# psoc6a2m register map
Vendor: Cypress Semiconductor; Series: psoc6a2m; File version: 1.0
CPU: CM4 r0p1, little endian, MPU, FPU, VTOR, 3 interrupt priority bits
Registers are 32-bit, read-write, reset 0x0 unless marked. A register's access mark holds for its fields unless they carry their own. Offsets are from the block's base; [hi:lo] are bit positions; lines under a group give offsets from that group; {n}, {i} and the like mark numbered series.

## DW0 — Datawire Controller
Base 0x40280000
Same registers: DW1 0x40290000
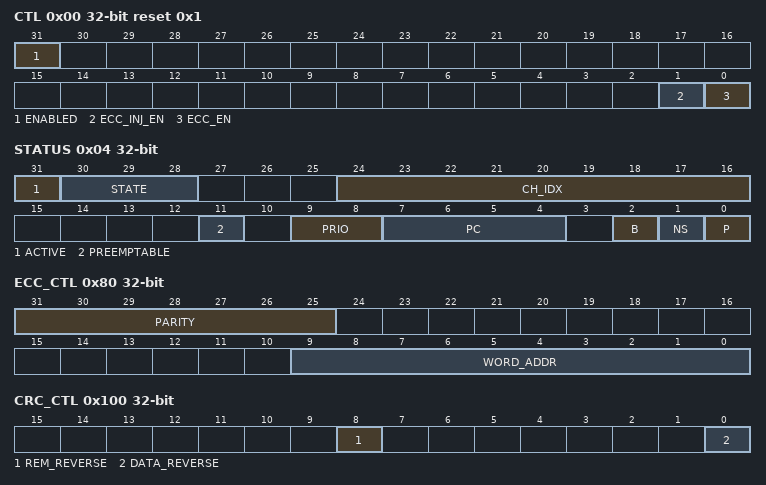
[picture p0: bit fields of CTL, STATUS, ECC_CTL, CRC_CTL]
0x00 CTL reset 0x1 — Control
  [31] ENABLED
  [1] ECC_INJ_EN — Enable parity injection for SRAM. When '1', the parity (ECC_CTL.PARITY) is used when a full 32-bit write is done to the ECC_CTL.WORD_ADDR word address of the SRAM.
  [0] ECC_EN — Enable ECC checking: '0': Disabled. '1': Enabled.
0x04 STATUS ro (reset mask 0xF0000000)
  [31] ACTIVE — Active channel present: '0': No. '1': Yes.
  [30:28] STATE — State of the DW controller. '0': Default/inactive state. '1': Loading descriptor. '2': Loading data element from source location. '3': Storing data element to destination location. '4': CRC functionality (only used for CRC transfer descriptor type). '5': Update of active control information (e.g. source and destination addresses) and wait for trigger de-activation. '6': Error.
  [24:16] CH_IDX — Active channel index.
  [11] PREEMPTABLE — Active channel preemptable.
  [9:8] PRIO — Active channel priority.
  [7:4] PC — Active channel protection context.
  [2] B — Active channel, non-bufferable/bufferable access control: '0': non-bufferable '1': bufferable.
  [1] NS — Active channel, secure/non-secure access control: '0': secure. '1': non-secure.
  [0] P — Active channel, user/privileged access control: '0': user mode. '1': privileged mode.
0x20 ACT_DESCR_CTL ro reset not defined — Active descriptor control
  [31:0] DATA
0x24 ACT_DESCR_SRC ro reset not defined — Active descriptor source
  [31:0] DATA
0x28 ACT_DESCR_DST ro reset not defined — Active descriptor destination
  [31:0] DATA
0x30 ACT_DESCR_X_CTL ro reset not defined — Active descriptor X loop control
  [31:0] DATA
0x34 ACT_DESCR_Y_CTL ro reset not defined — Active descriptor Y loop control
  [31:0] DATA
0x38 ACT_DESCR_NEXT_PTR ro reset not defined — Active descriptor next pointer
  [31:2] ADDR
0x40 ACT_SRC ro reset not defined — Active source
  [31:0] SRC_ADDR
0x44 ACT_DST ro reset not defined — Active destination
  [31:0] DST_ADDR
0x80 ECC_CTL — ECC control
  [31:25] PARITY — ECC parity to use for ECC error injection at address WORD_ADDR.
  [9:0] WORD_ADDR — Specifies the word address where an error will be injected. - On a write transfer to this SRAM word address and when CTL.ECC_INJ_EN bit is '1', the parity (PARITY) is injected.
0x100 CRC_CTL — CRC control
  [8] REM_REVERSE — Specifies whether the remainder is bit reversed (reversal is performed after XORing): '0': No. '1': Yes.
  [0] DATA_REVERSE — Specifies the bit order in which a data Byte is processed (reversal is performed after XORing): '0': Most significant bit (bit 1) first. '1': Least significant bit (bit 0) first.
0x110 CRC_DATA_CTL — CRC data control
  [7:0] DATA_XOR — Specifies a byte mask with which each data byte is XOR'd. The XOR is performed before data reversal.
0x120 CRC_POL_CTL — CRC polynomial control
  [31:0] POLYNOMIAL — CRC polynomial. The polynomial is represented WITHOUT the high order bit (this bit is always assumed '1'). The polynomial should be aligned/shifted such that the more significant bits (bit 31 and down) contain the polynomial and the less significant bits (bit 0 and up) contain padding '0's. Some frequently used polynomials: - CRC32: POLYNOMIAL is 0x04c11db7 (x^32 + x^26 + x^23 + x^22 + x^16 + x^12 + x^11 + x^10 + x^8 + x^7 + x^5 + x^4 + x^2 + x + 1). - CRC16: POLYNOMIAL is 0x80050000 (x^16 + x^15 + x^2 + 1, shifted by 16 bit positions). - CRC16 CCITT: POLYNOMIAL is 0x10210000 (x^16 + x^12 + x^5 + 1, shifted by 16 bit positions).
0x130 CRC_LFSR_CTL — CRC LFSR control
  [31:0] LFSR32 — State of a 32-bit Linear Feedback Shift Registers (LFSR) that is used to implement CRC. This register needs to be initialized by SW to provide the CRC seed value. The seed value should be aligned such that the more significant bits (bit 31 and down) contain the seed value and the less significant bits (bit 0 and up) contain padding '0's. Note that SW can write this field. This functionality can be used prevent information leakage (through either CRC_LFSR_CTL or CRC_REM_RESULT).
0x140 CRC_REM_CTL — CRC remainder control
  [31:0] REM_XOR — Specifies a mask with which the CRC_LFSR_CTL.LFSR32 register is XOR'd to produce a remainder. The XOR is performed before remainder reversal.
0x148 CRC_REM_RESULT ro — CRC remainder result
  [31:0] REM — Remainder value. The alignment of the remainder depends on CRC_REM_CTL0.REM_REVERSE: '0': the more significant bits (bit 31 and down) contain the remainder. '1': the less significant bits (bit 0 and up) contain the remainder. Note: This field is combinatorially derived from CRC_LFSR_CTL.LFSR32, CRC_CTL.REM_REVERSE and CRC_REM_CTL.REM_XOR.
{0x8000+0x40*i} CH_STRUCT[{i}] (i=0..28) group — DW channel structure
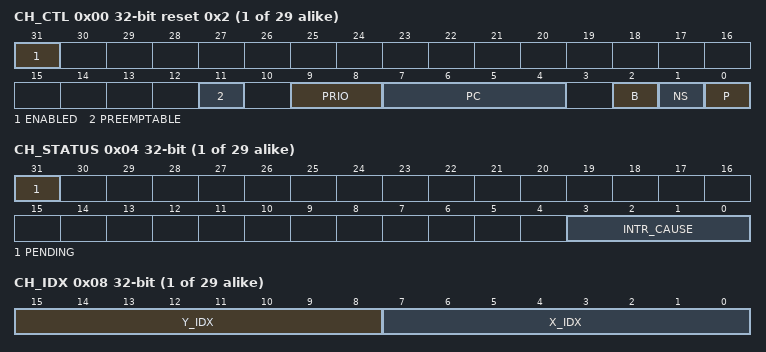
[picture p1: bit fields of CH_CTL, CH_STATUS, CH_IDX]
  0x00 CH_CTL reset 0x2 — Channel control
    [31] ENABLED, [11] PREEMPTABLE, [9:8] PRIO, [7:4] PC, [2] B, [1] NS, [0] P
  0x04 CH_STATUS ro reset not defined — Channel status
    [31] PENDING, [3:0] INTR_CAUSE
  0x08 CH_IDX reset not defined — Channel current indices
    [15:8] Y_IDX, [7:0] X_IDX
  0x0C CH_CURR_PTR reset not defined — Channel current descriptor pointer
    [31:2] ADDR
  0x10 INTR — Interrupt
    [0] CH
  0x14 INTR_SET — Interrupt set
    [0] CH
  0x18 INTR_MASK — Interrupt mask
    [0] CH
  0x1C INTR_MASKED ro — Interrupt masked
    [0] CH
  0x20 SRAM_DATA0 reset not defined
    [31:0] DATA
  0x24 SRAM_DATA1 reset not defined
    [31:0] DATA
